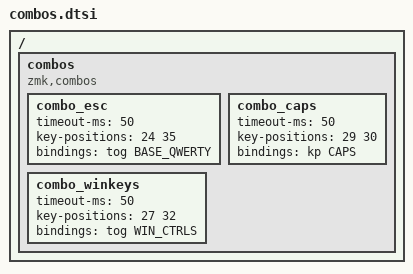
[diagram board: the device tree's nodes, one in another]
/ {
    combos {
        compatible = "zmk,combos";
        combo_esc {
            timeout-ms = <50>;
            key-positions = <24 35>;
            bindings = <&tog BASE_QWERTY>;
        };
        combo_winkeys {
            timeout-ms = <50>;
            key-positions = <27 32>;
            bindings = <&tog WIN_CTRLS>;
        };
        combo_caps {
            timeout-ms = <50>;
            key-positions = <29 30>;
            bindings = <&kp CAPS>;
        };
    };
};
